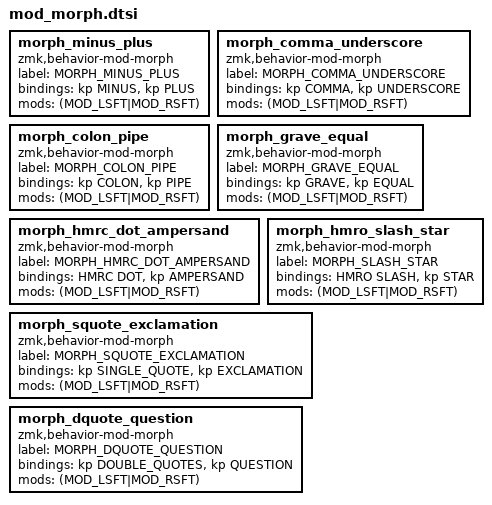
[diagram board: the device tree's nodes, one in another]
#include "hold_tap.dtsi"

morph_minus_plus: morph_minus_plus {
  compatible = "zmk,behavior-mod-morph";
  label = "MORPH_MINUS_PLUS";
  #binding-cells = <0>;
  bindings = <&kp MINUS>, <&kp PLUS>;
  mods = <(MOD_LSFT|MOD_RSFT)>;
};

morph_comma_underscore: morph_comma_underscore {
  compatible = "zmk,behavior-mod-morph";
  label = "MORPH_COMMA_UNDERSCORE";
  #binding-cells = <0>;
  bindings = <&kp COMMA>, <&kp UNDERSCORE>;
  mods = <(MOD_LSFT|MOD_RSFT)>;
};

morph_colon_pipe: morph_colon_pipe {
  compatible = "zmk,behavior-mod-morph";
  label = "MORPH_COLON_PIPE";
  #binding-cells = <0>;
  bindings = <&kp COLON>, <&kp PIPE>;
  mods = <(MOD_LSFT|MOD_RSFT)>;
};

morph_grave_equal: morph_grave_equal {
  compatible = "zmk,behavior-mod-morph";
  label = "MORPH_GRAVE_EQUAL";
  #binding-cells = <0>;
  bindings = <&kp GRAVE>, <&kp EQUAL>;
  mods = <(MOD_LSFT|MOD_RSFT)>;
};

morph_hmrc_dot_ampersand: morph_hmrc_dot_ampersand {
  compatible = "zmk,behavior-mod-morph";
  label = "MORPH_HMRC_DOT_AMPERSAND";
  #binding-cells = <0>;
  bindings = <HMRC DOT>, <&kp AMPERSAND>;
  mods = <(MOD_LSFT|MOD_RSFT)>;
};

morph_hmro_slash_star: morph_hmro_slash_star {
  compatible = "zmk,behavior-mod-morph";
  label = "MORPH_SLASH_STAR";
  #binding-cells = <0>;
  bindings = <HMRO SLASH>, <&kp STAR>;
  mods = <(MOD_LSFT|MOD_RSFT)>;
};

morph_squote_exclamation: morph_squote_exclamation {
  compatible = "zmk,behavior-mod-morph";
  label = "MORPH_SQUOTE_EXCLAMATION";
  #binding-cells = <0>;
  bindings = <&kp SINGLE_QUOTE>, <&kp EXCLAMATION>;
  mods = <(MOD_LSFT|MOD_RSFT)>;
};

morph_dquote_question: morph_dquote_question {
  compatible = "zmk,behavior-mod-morph";
  label = "MORPH_DQUOTE_QUESTION";
  #binding-cells = <0>;
  bindings = <&kp DOUBLE_QUOTES>, <&kp QUESTION>;
  mods = <(MOD_LSFT|MOD_RSFT)>;
};
